VERSION "created by canmatrix"

NS_ :

BS_:

BU_: User ADM_PC_LL25 ADM_PC_BC25 ADM_PC_BP25 ADM_PC_BI25

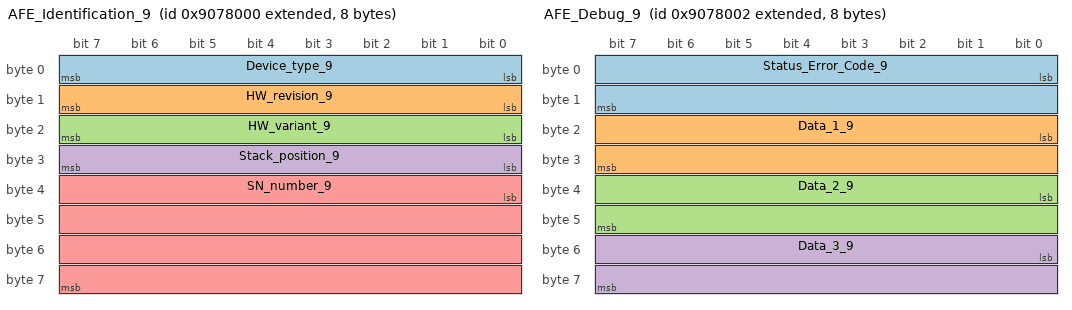
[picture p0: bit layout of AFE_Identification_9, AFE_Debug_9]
BO_ 2298970112 AFE_Identification_9: 8 ADM_PC_BP25
 SG_ Device_type_9 : 0|8@1+ (1,0) [0|255] "" Vector__XXX
 SG_ HW_revision_9 : 8|8@1+ (1,0) [0|255] "" Vector__XXX
 SG_ HW_variant_9 : 16|8@1+ (1,0) [0|255] "" Vector__XXX
 SG_ Stack_position_9 : 24|8@1+ (1,0) [0|255] "" Vector__XXX
 SG_ SN_number_9 : 32|32@1+ (1,0) [0|4294967295] "" Vector__XXX

BO_ 2298970113 AFE_FwInfo_9: 8 ADM_PC_BP25
 SG_ FW_info_mux_9 M : 56|8@1+ (1,0) [0|255] "" Vector__XXX
 SG_ FW_revision_0_9 m0 : 0|8@1+ (1,0) [0|255] "" Vector__XXX
 SG_ FW_revision_1_9 m0 : 8|8@1+ (1,0) [0|255] "" Vector__XXX
 SG_ FW_revision_2_9 m0 : 16|8@1+ (1,0) [0|255] "" Vector__XXX
 SG_ FW_revision_3_9 m0 : 24|8@1+ (1,0) [0|255] "" Vector__XXX
 SG_ FW_revision_4_9 m0 : 32|8@1+ (1,0) [0|255] "" Vector__XXX
 SG_ FW_revision_5_9 m0 : 40|8@1+ (1,0) [0|255] "" Vector__XXX
 SG_ FW_revision_6_9 m0 : 48|8@1+ (1,0) [0|255] "" Vector__XXX
 SG_ FW_revision_7_9 m1 : 0|8@1+ (1,0) [0|255] "" Vector__XXX
 SG_ FW_revision_8_9 m1 : 8|8@1+ (1,0) [0|255] "" Vector__XXX
 SG_ FW_revision_9_9 m1 : 16|8@1+ (1,0) [0|255] "" Vector__XXX
 SG_ FW_revision_10_9 m1 : 24|8@1+ (1,0) [0|255] "" Vector__XXX
 SG_ FW_revision_11_9 m1 : 32|8@1+ (1,0) [0|255] "" Vector__XXX
 SG_ FW_revision_12_9 m1 : 40|8@1+ (1,0) [0|255] "" Vector__XXX
 SG_ FW_revision_13_9 m1 : 48|8@1+ (1,0) [0|255] "" Vector__XXX
 SG_ FW_datecode_0_9 m2 : 0|8@1+ (1,0) [0|255] "" Vector__XXX
 SG_ FW_datecode_1_9 m2 : 8|8@1+ (1,0) [0|255] "" Vector__XXX
 SG_ FW_datecode_2_9 m2 : 16|8@1+ (1,0) [0|255] "" Vector__XXX
 SG_ FW_datecode_3_9 m2 : 24|8@1+ (1,0) [0|255] "" Vector__XXX
 SG_ FW_datecode_4_9 m2 : 32|8@1+ (1,0) [0|255] "" Vector__XXX
 SG_ FW_datecode_5_9 m2 : 40|8@1+ (1,0) [0|255] "" Vector__XXX
 SG_ FW_datecode_6_9 m2 : 48|8@1+ (1,0) [0|255] "" Vector__XXX
 SG_ FW_datecode_7_9 m3 : 0|8@1+ (1,0) [0|255] "" Vector__XXX
 SG_ FW_datecode_8_9 m3 : 8|8@1+ (1,0) [0|255] "" Vector__XXX
 SG_ FW_datecode_9_9 m3 : 16|8@1+ (1,0) [0|255] "" Vector__XXX
 SG_ FW_datecode_10_9 m3 : 24|8@1+ (1,0) [0|255] "" Vector__XXX
 SG_ FW_datecode_11_9 m3 : 32|8@1+ (1,0) [0|255] "" Vector__XXX
 SG_ FW_datecode_12_9 m3 : 40|8@1+ (1,0) [0|255] "" Vector__XXX
 SG_ FW_datecode_13_9 m3 : 48|8@1+ (1,0) [0|255] "" Vector__XXX

BO_ 2298970125 _AFE_Boot_FwInfo_9: 8 ADM_PC_BP25
 SG_ Boot_FW_info_mux_9 M : 56|8@1+ (1,0) [0|255] "" Vector__XXX
 SG_ FW_revision_0_9 m0 : 0|8@1+ (1,0) [0|255] "" Vector__XXX
 SG_ FW_revision_1_9 m0 : 8|8@1+ (1,0) [0|255] "" Vector__XXX
 SG_ FW_revision_2_9 m0 : 16|8@1+ (1,0) [0|255] "" Vector__XXX
 SG_ FW_revision_3_9 m0 : 24|8@1+ (1,0) [0|255] "" Vector__XXX
 SG_ FW_revision_4_9 m0 : 32|8@1+ (1,0) [0|255] "" Vector__XXX
 SG_ FW_revision_5_9 m0 : 40|8@1+ (1,0) [0|255] "" Vector__XXX
 SG_ FW_revision_6_9 m0 : 48|8@1+ (1,0) [0|255] "" Vector__XXX
 SG_ FW_revision_7_9 m1 : 0|8@1+ (1,0) [0|255] "" Vector__XXX
 SG_ FW_revision_8_9 m1 : 8|8@1+ (1,0) [0|255] "" Vector__XXX
 SG_ FW_revision_9_9 m1 : 16|8@1+ (1,0) [0|255] "" Vector__XXX
 SG_ FW_revision_10_9 m1 : 24|8@1+ (1,0) [0|255] "" Vector__XXX
 SG_ FW_revision_11_9 m1 : 32|8@1+ (1,0) [0|255] "" Vector__XXX
 SG_ FW_revision_12_9 m1 : 40|8@1+ (1,0) [0|255] "" Vector__XXX
 SG_ FW_revision_13_9 m1 : 48|8@1+ (1,0) [0|255] "" Vector__XXX
 SG_ FW_datecode_0_9 m2 : 0|8@1+ (1,0) [0|255] "" Vector__XXX
 SG_ FW_datecode_1_9 m2 : 8|8@1+ (1,0) [0|255] "" Vector__XXX
 SG_ FW_datecode_2_9 m2 : 16|8@1+ (1,0) [0|255] "" Vector__XXX
 SG_ FW_datecode_3_9 m2 : 24|8@1+ (1,0) [0|255] "" Vector__XXX
 SG_ FW_datecode_4_9 m2 : 32|8@1+ (1,0) [0|255] "" Vector__XXX
 SG_ FW_datecode_5_9 m2 : 40|8@1+ (1,0) [0|255] "" Vector__XXX
 SG_ FW_datecode_6_9 m2 : 48|8@1+ (1,0) [0|255] "" Vector__XXX
 SG_ FW_datecode_7_9 m3 : 0|8@1+ (1,0) [0|255] "" Vector__XXX
 SG_ FW_datecode_8_9 m3 : 8|8@1+ (1,0) [0|255] "" Vector__XXX
 SG_ FW_datecode_9_9 m3 : 16|8@1+ (1,0) [0|255] "" Vector__XXX
 SG_ FW_datecode_10_9 m3 : 24|8@1+ (1,0) [0|255] "" Vector__XXX
 SG_ FW_datecode_11_9 m3 : 32|8@1+ (1,0) [0|255] "" Vector__XXX
 SG_ FW_datecode_12_9 m3 : 40|8@1+ (1,0) [0|255] "" Vector__XXX
 SG_ FW_datecode_13_9 m3 : 48|8@1+ (1,0) [0|255] "" Vector__XXX

BO_ 2298970114 AFE_Debug_9: 8 ADM_PC_BP25
 SG_ Status_Error_Code_9 : 0|16@1+ (1,0) [0|65535] "" Vector__XXX
 SG_ Data_1_9 : 16|16@1+ (1,0) [0|65535] "" Vector__XXX
 SG_ Data_2_9 : 32|16@1+ (1,0) [0|65535] "" Vector__XXX
 SG_ Data_3_9 : 48|16@1+ (1,0) [0|65535] "" Vector__XXX

BO_ 2298970119 AFE_Status_9: 8 ADM_PC_BP25
 SG_ Running_9 : 0|1@1+ (1,0) [0|1] "" Vector__XXX
 SG_ PWM_9 : 1|1@1+ (1,0) [0|1] "" Vector__XXX
 SG_ Current_dc_loop_mode_9 : 2|1@1+ (1,0) [0|1] "" Vector__XXX
 SG_ Current_ac_loop_mode_9 : 3|1@1+ (1,0) [0|1] "" Vector__XXX
 SG_ Buck_9 : 5|1@1+ (1,0) [0|1] "" Vector__XXX
 SG_ Boost_9 : 6|1@1+ (1,0) [0|1] "" Vector__XXX
 SG_ Precharge_dc_buck_mode_9 : 7|1@1+ (1,0) [0|1] "" Vector__XXX
 SG_ Precharge_dc_boost_mode_9 : 8|1@1+ (1,0) [0|1] "" Vector__XXX
 SG_ Rectifier_3ph_9 : 9|1@1+ (1,0) [0|1] "" Vector__XXX
 SG_ Stack_mode_9 : 10|1@1+ (1,0) [0|1] "" Vector__XXX
 SG_ Master_9 : 11|1@1+ (1,0) [0|1] "" Vector__XXX
 SG_ Slave_9 : 12|1@1+ (1,0) [0|1] "" Vector__XXX
 SG_ Inverter_1ph_9 : 13|1@1+ (1,0) [0|1] "" Vector__XXX
 SG_ Boost_Neutral_9 : 14|1@1+ (1,0) [0|1] "" Vector__XXX
 SG_ Rectifier_1ph_9 : 15|1@1+ (1,0) [0|1] "" Vector__XXX
 SG_ Inverter_3ph_9 : 16|1@1+ (1,0) [0|1] "" Vector__XXX
 SG_ Ready_9 : 17|1@1+ (1,0) [0|1] "" Vector__XXX
 SG_ Inverter_1ph_Sync_9 : 18|1@1+ (1,0) [0|1] "" Vector__XXX
 SG_ Neutral_9 : 19|1@1+ (1,0) [0|1] "" Vector__XXX
 SG_ Rectifier_1ph_Buck_9 : 20|1@1+ (1,0) [0|1] "" Vector__XXX
 SG_ Inverter_1ph_Boost_9 : 21|1@1+ (1,0) [0|1] "" Vector__XXX
 SG_ Rectifier_distributed_9 : 22|1@1+ (1,0) [0|1] "" Vector__XXX
 SG_ MPPT_buck_9 : 23|1@1+ (1,0) [0|1] "" Vector__XXX
 SG_ MPPT_boost_9 : 24|1@1+ (1,0) [0|1] "" Vector__XXX
 SG_ Buck_2p_float_9 : 25|1@1+ (1,0) [0|1] "" Vector__XXX
 SG_ Inverter_1ph_Distributed_9 : 26|1@1+ (1,0) [0|1] "" Vector__XXX

BO_ 2298970118 AFE_Faults_9: 3 ADM_PC_BP25
 SG_ Protection_trip_internal_9 : 0|1@1+ (1,0) [0|1] "" Vector__XXX
 SG_ Protection_trip_external_9 : 1|1@1+ (1,0) [0|1] "" Vector__XXX
 SG_ Phase_U_overcurrent_9 : 2|1@1+ (1,0) [0|1] "" Vector__XXX
 SG_ Phase_U_overvoltage_9 : 3|1@1+ (1,0) [0|1] "" Vector__XXX
 SG_ Phase_U_undervoltage_9 : 4|1@1+ (1,0) [0|1] "" Vector__XXX
 SG_ Phase_V_overvoltage_9 : 5|1@1+ (1,0) [0|1] "" Vector__XXX
 SG_ Phase_V_undervoltage_9 : 6|1@1+ (1,0) [0|1] "" Vector__XXX
 SG_ Phase_V_overcurrent_9 : 7|1@1+ (1,0) [0|1] "" Vector__XXX
 SG_ Phase_W_overvoltage_9 : 8|1@1+ (1,0) [0|1] "" Vector__XXX
 SG_ Phase_W_undervoltage_9 : 9|1@1+ (1,0) [0|1] "" Vector__XXX
 SG_ Phase_W_overcurrent_9 : 10|1@1+ (1,0) [0|1] "" Vector__XXX
 SG_ DC_undervoltage_9 : 11|1@1+ (1,0) [0|1] "" Vector__XXX
 SG_ DC_overvoltage_9 : 12|1@1+ (1,0) [0|1] "" Vector__XXX
 SG_ MOSFET_overtemperature_9 : 13|1@1+ (1,0) [0|1] "" Vector__XXX
 SG_ Inductor_overtemperature_9 : 14|1@1+ (1,0) [0|1] "" Vector__XXX
 SG_ Keep_Alive_not_served_9 : 15|1@1+ (1,0) [0|1] "" Vector__XXX
 SG_ PLL_not_locked_9 : 16|1@1+ (1,0) [0|1] "" Vector__XXX
 SG_ NFO_9 : 20|1@1+ (1,0) [0|1] "" Vector__XXX
 SG_ Measurement_system_failure_9 : 21|1@1+ (1,0) [0|1] "" Vector__XXX
 SG_ EEPROM_failure_9 : 22|1@1+ (1,0) [0|1] "" Vector__XXX
 SG_ System_9 : 23|1@1+ (1,0) [0|1] "" Vector__XXX

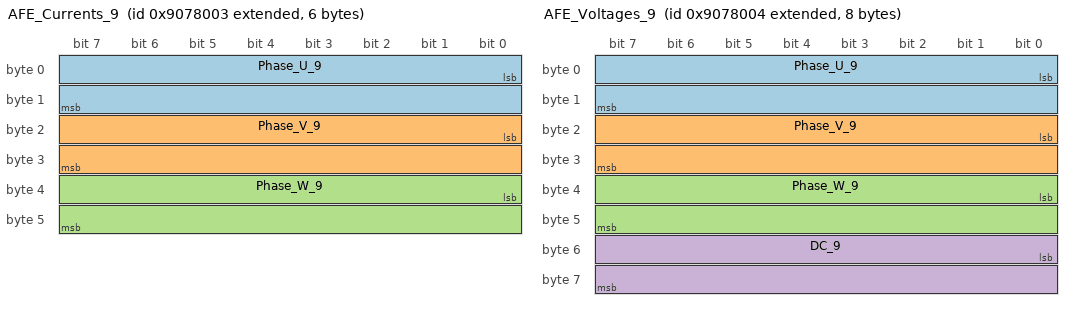
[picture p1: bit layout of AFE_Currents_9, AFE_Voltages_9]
BO_ 2298970115 AFE_Currents_9: 6 ADM_PC_BP25
 SG_ Phase_U_9 : 0|16@1- (0.01,0) [-327.68|327.67] "A" Vector__XXX
 SG_ Phase_V_9 : 16|16@1- (0.01,0) [-327.68|327.67] "A" Vector__XXX
 SG_ Phase_W_9 : 32|16@1- (0.01,0) [-327.68|327.67] "A" Vector__XXX

BO_ 2298970128 AFE_DC_Bus_current_9: 2 ADM_PC_BP25
 SG_ Bus_current_9 : 0|16@1- (0.01,0) [-327.68|327.67] "A" Vector__XXX

BO_ 2298970126 _AFE_Broadcast_9: 8 ADM_PC_BP25
 SG_ Diagnostics_Index_9 M : 56|8@1+ (1,0) [0|255] "" Vector__XXX
 SG_ Phase_U_9 m1 : 8|16@1- (0.01,0) [-327.68|327.67] "A" ADM_PC_BP25
 SG_ Phase_V_9 m1 : 24|16@1- (0.01,0) [-327.68|327.67] "A" ADM_PC_BP25
 SG_ Phase_W_9 m1 : 40|16@1- (0.01,0) [-327.68|327.67] "A" ADM_PC_BP25
 SG_ Stack_position_9 : 0|5@1+ (1,0) [0|31] "" ADM_PC_BP25
 SG_ Group_ID_9 : 5|3@1+ (1,0) [0|7] "" ADM_PC_BP25

BO_ 2298970116 AFE_Voltages_9: 8 ADM_PC_BP25
 SG_ Phase_U_9 : 0|16@1- (0.1,0) [-3276.8|3276.7] "V" Vector__XXX
 SG_ Phase_V_9 : 16|16@1- (0.1,0) [-3276.8|3276.7] "V" Vector__XXX
 SG_ Phase_W_9 : 32|16@1- (0.1,0) [-3276.8|3276.7] "V" Vector__XXX
 SG_ DC_9 : 48|16@1- (0.1,0) [-3276.8|3276.7] "V" Vector__XXX

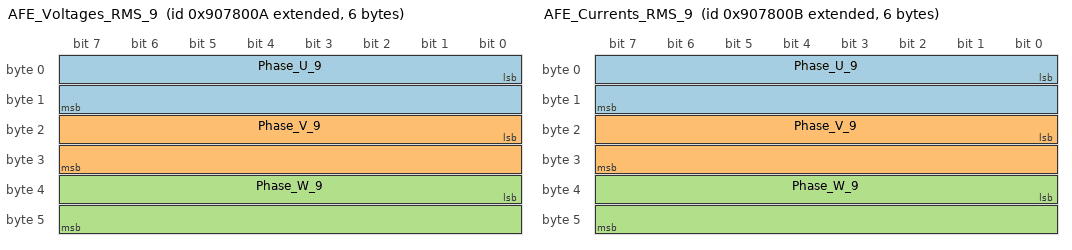
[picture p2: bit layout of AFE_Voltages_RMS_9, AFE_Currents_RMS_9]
BO_ 2298970122 AFE_Voltages_RMS_9: 6 ADM_PC_BP25
 SG_ Phase_U_9 : 0|16@1+ (0.1,0) [0|6553.5] "V" Vector__XXX
 SG_ Phase_V_9 : 16|16@1+ (0.1,0) [0|6553.5] "V" Vector__XXX
 SG_ Phase_W_9 : 32|16@1+ (0.1,0) [0|6553.5] "V" Vector__XXX

BO_ 2298970123 AFE_Currents_RMS_9: 6 ADM_PC_BP25
 SG_ Phase_U_9 : 0|16@1+ (0.01,0) [0.00|655.35] "A" Vector__XXX
 SG_ Phase_V_9 : 16|16@1+ (0.01,0) [0.00|655.35] "A" Vector__XXX
 SG_ Phase_W_9 : 32|16@1+ (0.01,0) [0.00|655.35] "A" Vector__XXX

BO_ 2298970124 AFE_Mains_9: 4 ADM_PC_BP25
 SG_ Frequency_9 : 0|16@1+ (0.01,0) [0.00|655.35] "Hz" Vector__XXX
 SG_ Phase_9 : 16|16@1- (0.1,0) [-3276.8|3276.7] "Deg." Vector__XXX

BO_ 2298970117 AFE_Temperatures_9: 4 ADM_PC_BP25
 SG_ Temp_Bridge_9 : 0|16@1- (0.01,0) [-327.68|327.67] "°C" Vector__XXX
 SG_ Temp_Inductors_9 : 16|16@1- (0.01,0) [-327.68|327.67] "°C" Vector__XXX

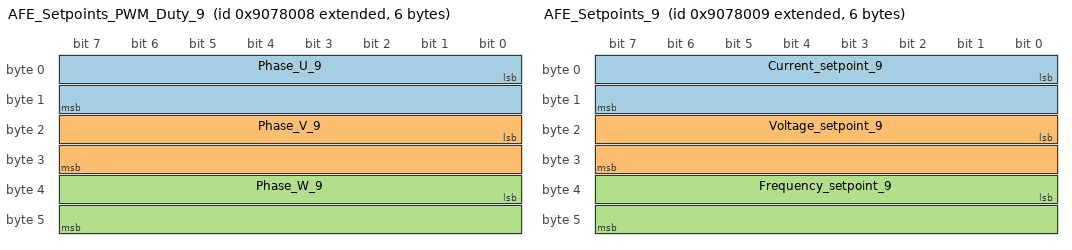
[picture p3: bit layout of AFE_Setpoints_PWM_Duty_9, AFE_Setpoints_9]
BO_ 2298970120 AFE_Setpoints_PWM_Duty_9: 6 ADM_PC_BP25
 SG_ Phase_U_9 : 0|16@1+ (0.001525902,0) [0E-009|99.999987570] "%" Vector__XXX
 SG_ Phase_V_9 : 16|16@1+ (0.001525902,0) [0E-009|99.999987570] "%" Vector__XXX
 SG_ Phase_W_9 : 32|16@1+ (0.001525902,0) [0E-009|99.999987570] "%" Vector__XXX

BO_ 2298970121 AFE_Setpoints_9: 6 ADM_PC_BP25
 SG_ Current_setpoint_9 : 0|16@1- (0.01,0) [-327.68|327.67] "A" Vector__XXX
 SG_ Voltage_setpoint_9 : 16|16@1+ (0.1,0) [0|6553.5] "V" Vector__XXX
 SG_ Frequency_setpoint_9 : 32|16@1+ (0.01,0) [0.00|655.35] "Hz" Vector__XXX

BO_ 2298937440 AFE_Keep_Alive_9: 1 User
 SG_ Keep_Alive_Enable_9 : 0|1@1+ (1,0) [0|1] "" ADM_PC_BP25

BO_ 2298937408 AFE_Mode_Control_9: 8 User
 SG_ Converter_ON_9 : 0|1@1+ (1,0) [0|1] "" ADM_PC_BP25
 SG_ PWM_ON_9 : 1|1@1+ (1,0) [0|1] "" ADM_PC_BP25
 SG_ DC_Current_feedback_ON_9 : 2|1@1+ (1,0) [0|1] "" ADM_PC_BP25
 SG_ AC_Current_feedback_ON_9 : 3|1@1+ (1,0) [0|1] "" ADM_PC_BP25
 SG_ Buck_ON_9 : 5|1@1+ (1,0) [0|1] "" ADM_PC_BP25
 SG_ Boost_ON_9 : 6|1@1+ (1,0) [0|1] "" ADM_PC_BP25
 SG_ Rectifier_3ph_ON_9 : 9|1@1+ (1,0) [0|1] "" ADM_PC_BP25
 SG_ Inverter_1ph_ON_9 : 10|1@1+ (1,0) [0|1] "" ADM_PC_BP25
 SG_ Rectifier_1ph_ON_9 : 11|1@1+ (1,0) [0|1] "" ADM_PC_BP25
 SG_ Boost_Neutral_ON_9 : 12|1@1+ (1,0) [0|1] "" ADM_PC_BP25
 SG_ Inverter_3ph_ON_9 : 13|1@1+ (1,0) [0|1] "" ADM_PC_BP25
 SG_ Inverter_1ph_Sync_ON_9 : 14|1@1+ (1,0) [0|1] "" ADM_PC_BP25
 SG_ Neutral_ON_9 : 15|1@1+ (1,0) [0|1] "" ADM_PC_BP25
 SG_ Rectifier_1ph_Buck_ON_9 : 16|1@1+ (1,0) [0|1] "" ADM_PC_BP25
 SG_ Inverter_1ph_Boost_ON_9 : 17|1@1+ (1,0) [0|1] "" ADM_PC_BP25
 SG_ Rectifier_Distributed_ON_9 : 18|1@1+ (1,0) [0|1] "" ADM_PC_BP25
 SG_ MPPT_buck_ON_9 : 19|1@1+ (1,0) [0|1] "" ADM_PC_BP25
 SG_ MPPT_boost_ON_9 : 20|1@1+ (1,0) [0|1] "" ADM_PC_BP25
 SG_ Buck_2p_float_ON_9 : 21|1@1+ (1,0) [0|1] "" ADM_PC_BP25
 SG_ Inverter_1ph_Distributed_ON_9 : 22|1@1+ (1,0) [0|1] "" ADM_PC_BP25

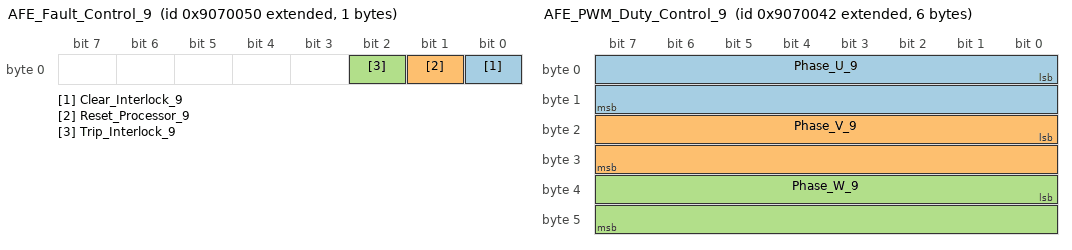
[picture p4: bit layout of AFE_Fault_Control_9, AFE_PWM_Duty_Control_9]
BO_ 2298937424 AFE_Fault_Control_9: 1 User
 SG_ Clear_Interlock_9 : 0|1@1+ (1,0) [0|1] "" ADM_PC_BP25
 SG_ Reset_Processor_9 : 1|1@1+ (1,0) [0|1] "" ADM_PC_BP25
 SG_ Trip_Interlock_9 : 2|1@1+ (1,0) [0|1] "" ADM_PC_BP25

BO_ 2298937409 AFE_Reactive_Current_Setpoint_Co: 2 User
 SG_ Reactive_current_setpoint_9 : 0|16@1- (0.01,0) [-150|150] "A" ADM_PC_BP25

BO_ 2298937410 AFE_PWM_Duty_Control_9: 6 User
 SG_ Phase_U_9 : 0|16@1+ (0.001525902,0) [0E-009|99.999987570] "%" ADM_PC_BP25
 SG_ Phase_V_9 : 16|16@1+ (0.001525902,0) [0E-009|99.999987570] "%" ADM_PC_BP25
 SG_ Phase_W_9 : 32|16@1+ (0.001525902,0) [0E-009|99.999987570] "%" ADM_PC_BP25

BO_ 2298937411 AFE_Current_Setpoint_Control_9: 2 User
 SG_ Current_setpoint_9 : 0|16@1- (0.01,0) [-150|150] "A" ADM_PC_BP25

BO_ 2298937412 AFE_Voltage_Setpoint_Control_9: 2 User
 SG_ Voltage_setpoint_9 : 0|16@1+ (0.1,0) [0|1500] "V" ADM_PC_BP25

BO_ 2298937416 AFE_Frequency_Setpoint_Control_9: 2 User
 SG_ Frequency_setpoint_9 : 0|16@1+ (0.01,0) [40|70] "Hz" ADM_PC_BP25

BO_ 2298937417 AFE_Phase_Setpoint_Control_9: 2 User
 SG_ Phase_setpoint_9 : 0|16@1+ (1,0) [0|360] "deg" ADM_PC_BP25

BO_ 2298937456 AFE_Rectifier_Setpoint_Control_9: 8 User
 SG_ Voltage_setpoint_2_9 : 0|16@1+ (0.1,0) [0|1500] "V" ADM_PC_BP25
 SG_ Current_setpoint_2_9 : 16|16@1- (0.01,0) [-150|150] "A" ADM_PC_BP25

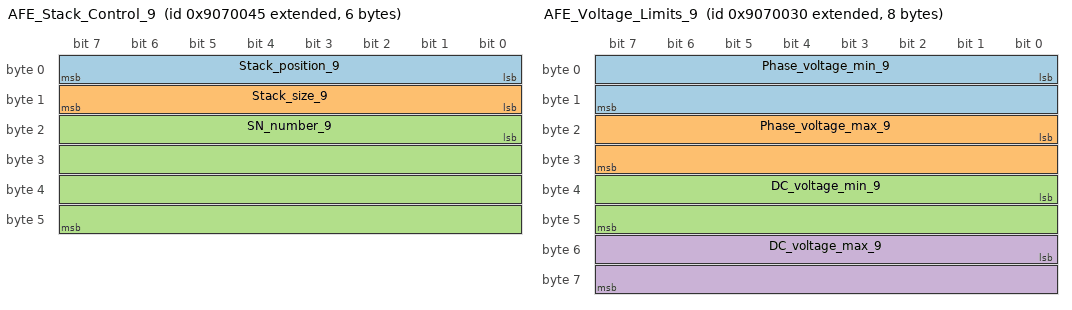
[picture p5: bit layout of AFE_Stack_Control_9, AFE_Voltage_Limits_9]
BO_ 2298937413 AFE_Stack_Control_9: 6 User
 SG_ Stack_position_9 : 0|8@1+ (1,0) [0|255] "" ADM_PC_BP25
 SG_ Stack_size_9 : 8|8@1+ (1,0) [0|255] "" ADM_PC_BP25
 SG_ SN_number_9 : 16|32@1+ (1,0) [0|4294967295] "" ADM_PC_BP25

BO_ 2298937392 AFE_Voltage_Limits_9: 8 User
 SG_ Phase_voltage_min_9 : 0|16@1- (0.1,0) [0|3276.7] "V" ADM_PC_BP25
 SG_ Phase_voltage_max_9 : 16|16@1- (0.1,0) [-3276.8|850] "V" ADM_PC_BP25
 SG_ DC_voltage_min_9 : 32|16@1- (0.1,0) [0|3276.7] "V" ADM_PC_BP25
 SG_ DC_voltage_max_9 : 48|16@1- (0.1,0) [-3276.8|850] "V" ADM_PC_BP25

BO_ 2298937393 AFE_Current_Limits_9: 4 User
 SG_ Phase_current_min_9 : 0|16@1- (0.01,0) [-60|60] "A" ADM_PC_BP25
 SG_ Phase_current_max_9 : 16|16@1- (0.01,0) [-60|60] "A" ADM_PC_BP25

BO_ 2298937420 AFE_Group_Control_9: 1 User
 SG_ Group_ID_9 : 0|8@1+ (1,0) [0|255] "" ADM_PC_BP25

BO_ 2298970127 AFE_Group_Info_9: 1 ADM_PC_BP25
 SG_ Group_ID_9 : 0|8@1+ (1,0) [0|255] "" Vector__XXX

BO_ 2298937441 AFE_System_Flags_Control_9: 8 User
 SG_ Factory_mode_9 : 0|1@1+ (1,0) [0|1] "" ADM_PC_BP25
 SG_ Silent_CAN_mode_9 : 1|1@1+ (1,0) [0|1] "" ADM_PC_BP25

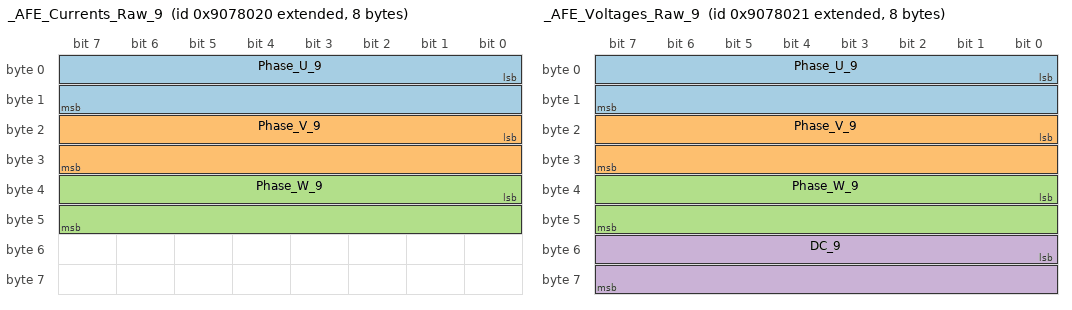
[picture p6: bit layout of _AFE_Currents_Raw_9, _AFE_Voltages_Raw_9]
BO_ 2298970144 _AFE_Currents_Raw_9: 8 ADM_PC_BP25
 SG_ Phase_U_9 : 0|16@1- (1,0) [-32768|32767] "" Vector__XXX
 SG_ Phase_V_9 : 16|16@1- (1,0) [-32768|32767] "" Vector__XXX
 SG_ Phase_W_9 : 32|16@1- (1,0) [-32768|32767] "" Vector__XXX

BO_ 2298970145 _AFE_Voltages_Raw_9: 8 ADM_PC_BP25
 SG_ Phase_U_9 : 0|16@1- (1,0) [-32768|32767] "" Vector__XXX
 SG_ Phase_V_9 : 16|16@1- (1,0) [-32768|32767] "" Vector__XXX
 SG_ Phase_W_9 : 32|16@1- (1,0) [-32768|32767] "" Vector__XXX
 SG_ DC_9 : 48|16@1- (1,0) [-32768|32767] "" Vector__XXX

BO_ 2298937418 _AFE_ADC_Calibration_Mode_9: 1 User
 SG_ Calibration_Index_9 M : 2|5@1+ (1,0) [0|31] "" Vector__XXX
 SG_ Current_U_9 m1 : 0|2@1+ (1,0) [0|3] "" ADM_PC_BP25
 SG_ Current_V_9 m2 : 0|2@1+ (1,0) [0|3] "" ADM_PC_BP25
 SG_ Current_W_9 m3 : 0|2@1+ (1,0) [0|3] "" ADM_PC_BP25
 SG_ Voltage_U_9 m4 : 0|2@1+ (1,0) [0|3] "" ADM_PC_BP25
 SG_ Voltage_V_9 m5 : 0|2@1+ (1,0) [0|3] "" ADM_PC_BP25
 SG_ Voltage_W_9 m6 : 0|2@1+ (1,0) [0|3] "" ADM_PC_BP25
 SG_ Voltage_DC_9 m7 : 0|2@1+ (1,0) [0|3] "" ADM_PC_BP25
 SG_ start_9 : 7|1@1+ (1,0) [0|1] "" ADM_PC_BP25

BO_ 2298937419 _AFE_ADC_Calibration_Setpoint_9: 3 User
 SG_ Calibration_Index_9 M : 16|5@1+ (1,0) [0|31] "" Vector__XXX
 SG_ Current_U_9 m1 : 0|16@1- (0.01,0) [-100|100] "A" ADM_PC_BP25
 SG_ Current_V_9 m2 : 0|16@1- (0.01,0) [-100|100] "A" ADM_PC_BP25
 SG_ Current_W_9 m3 : 0|16@1- (0.01,0) [-100|100] "A" ADM_PC_BP25
 SG_ Voltage_U_9 m4 : 0|16@1+ (0.1,0) [0|1500] "V" ADM_PC_BP25
 SG_ Voltage_V_9 m5 : 0|16@1+ (0.1,0) [0|1500] "V" ADM_PC_BP25
 SG_ Voltage_W_9 m6 : 0|16@1+ (0.1,0) [0|1500] "V" ADM_PC_BP25
 SG_ Voltage_DC_9 m7 : 0|16@1+ (0.1,0) [0|1500] "V" ADM_PC_BP25
 SG_ point_9 : 21|3@1+ (1,0) [0|7] "" ADM_PC_BP25

BO_ 2298937414 _AFE_Calibration_Offset_Update_9: 6 User
 SG_ Calibration_Index_9 M : 16|16@1+ (1,0) [0|65535] "" Vector__XXX
 SG_ Current_U_9 m0 : 0|16@1- (1,0) [-32768|32767] "ADC Counts" ADM_PC_BP25
 SG_ Current_V_9 m1 : 0|16@1- (1,0) [-32768|32767] "ADC Counts" ADM_PC_BP25
 SG_ Current_W_9 m2 : 0|16@1- (1,0) [-32768|32767] "ADC Counts" ADM_PC_BP25
 SG_ Voltage_U_9 m3 : 0|16@1- (1,0) [-32768|32767] "ADC Counts" ADM_PC_BP25
 SG_ Voltage_V_9 m4 : 0|16@1- (1,0) [-32768|32767] "ADC Counts" ADM_PC_BP25
 SG_ Voltage_W_9 m5 : 0|16@1- (1,0) [-32768|32767] "ADC Counts" ADM_PC_BP25
 SG_ Voltage_DC_9 m6 : 0|16@1- (1,0) [-32768|32767] "ADC Counts" ADM_PC_BP25
 SG_ CRC_9 : 32|16@1+ (1,0) [0|65535] "-" ADM_PC_BP25

BO_ 2298937415 _AFE_Calibration_Scale_Update_9: 6 User
 SG_ Calibration_Index_9 M : 16|16@1+ (1,0) [0|65535] "" Vector__XXX
 SG_ Current_U_9 m0 : 0|16@1- (0.0000152587890625,0) [-0.5000000000000000|0.4999847412109375] "scale = 1.0 + value" ADM_PC_BP25
 SG_ Current_V_9 m1 : 0|16@1- (0.0000152587890625,0) [-0.5000000000000000|0.4999847412109375] "scale = 1.0 + value" ADM_PC_BP25
 SG_ Current_W_9 m2 : 0|16@1- (0.0000152587890625,0) [-0.5000000000000000|0.4999847412109375] "scale = 1.0 + value" ADM_PC_BP25
 SG_ Voltage_U_9 m3 : 0|16@1- (0.0000152587890625,0) [-0.5000000000000000|0.4999847412109375] "scale = 1.0 + value" ADM_PC_BP25
 SG_ Voltage_V_9 m4 : 0|16@1- (0.0000152587890625,0) [-0.5000000000000000|0.4999847412109375] "scale = 1.0 + value" ADM_PC_BP25
 SG_ Voltage_W_9 m5 : 0|16@1- (0.0000152587890625,0) [-0.5000000000000000|0.4999847412109375] "scale = 1.0 + value" ADM_PC_BP25
 SG_ Voltage_DC_9 m6 : 0|16@1- (0.0000152587890625,0) [-0.5000000000000000|0.4999847412109375] "scale = 1.0 + value" ADM_PC_BP25
 SG_ CRC_9 : 32|16@1+ (1,0) [0|65535] "-" ADM_PC_BP25

BO_ 2298970193 _AFE_Calibration_Adc_Scale_9: 6 ADM_PC_BP25
 SG_ Adc_Index_9 M : 32|16@1+ (1,0) [0|65535] "" Vector__XXX
 SG_ Current_U_9 m0 : 0|32@1+ (1,0) [0|4294967295] "1 / adc_bins" User
 SG_ Current_V_9 m1 : 0|32@1+ (1,0) [0|4294967295] "1 / adc_bins" User
 SG_ Current_W_9 m2 : 0|32@1+ (1,0) [0|4294967295] "1 / adc_bins" User
 SG_ Voltage_U_9 m3 : 0|32@1+ (1,0) [0|4294967295] "1 / adc_bins" User
 SG_ Voltage_V_9 m4 : 0|32@1+ (1,0) [0|4294967295] "1 / adc_bins" User
 SG_ Voltage_W_9 m5 : 0|32@1+ (1,0) [0|4294967295] "1 / adc_bins" User
 SG_ Voltage_DC_9 m6 : 0|32@1+ (1,0) [0|4294967295] "1 / adc_bins" User

BO_ 2298970194 _AFE_Calibration_Adc_Fs_9: 6 ADM_PC_BP25
 SG_ Adc_Index_9 M : 32|16@1+ (1,0) [0|65535] "" Vector__XXX
 SG_ Current_U_9 m0 : 0|32@1+ (1,0) [0|4294967295] "Fullscale" User
 SG_ Current_V_9 m1 : 0|32@1+ (1,0) [0|4294967295] "Fullscale" User
 SG_ Current_W_9 m2 : 0|32@1+ (1,0) [0|4294967295] "Fullscale" User
 SG_ Voltage_U_9 m3 : 0|32@1+ (1,0) [0|4294967295] "Fullscale" User
 SG_ Voltage_V_9 m4 : 0|32@1+ (1,0) [0|4294967295] "Fullscale" User
 SG_ Voltage_W_9 m5 : 0|32@1+ (1,0) [0|4294967295] "Fullscale" User
 SG_ Voltage_DC_9 m6 : 0|32@1+ (1,0) [0|4294967295] "Fullscale" User

BO_ 2298970195 _AFE_Calibration_Adc_Offset_9: 4 ADM_PC_BP25
 SG_ Adc_Index_9 M : 16|16@1+ (1,0) [0|65535] "" Vector__XXX
 SG_ Current_U_9 m0 : 0|16@1- (1,0) [-32768|32767] "-" User
 SG_ Current_V_9 m1 : 0|16@1- (1,0) [-32768|32767] "-" User
 SG_ Current_W_9 m2 : 0|16@1- (1,0) [-32768|32767] "-" User
 SG_ Voltage_U_9 m3 : 0|16@1- (1,0) [-32768|32767] "-" User
 SG_ Voltage_V_9 m4 : 0|16@1- (1,0) [-32768|32767] "-" User
 SG_ Voltage_W_9 m5 : 0|16@1- (1,0) [-32768|32767] "-" User
 SG_ Voltage_DC_9 m6 : 0|16@1- (1,0) [-32768|32767] "-" User

BO_ 2298970196 _AFE_Calibration_Adc_Gain_9: 4 ADM_PC_BP25
 SG_ Adc_Index_9 M : 16|16@1+ (1,0) [0|65535] "" Vector__XXX
 SG_ Current_U_9 m0 : 0|16@1- (1,0) [-32768|32767] "-" User
 SG_ Current_V_9 m1 : 0|16@1- (1,0) [-32768|32767] "-" User
 SG_ Current_W_9 m2 : 0|16@1- (1,0) [-32768|32767] "-" User
 SG_ Voltage_U_9 m3 : 0|16@1- (1,0) [-32768|32767] "-" User
 SG_ Voltage_V_9 m4 : 0|16@1- (1,0) [-32768|32767] "-" User
 SG_ Voltage_W_9 m5 : 0|16@1- (1,0) [-32768|32767] "-" User
 SG_ Voltage_DC_9 m6 : 0|16@1- (1,0) [-32768|32767] "-" User

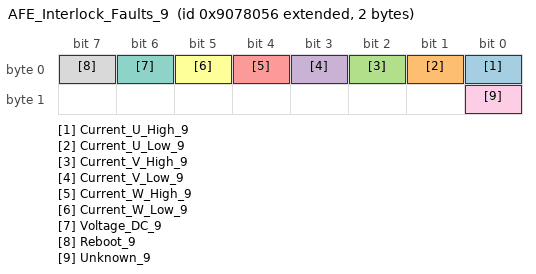
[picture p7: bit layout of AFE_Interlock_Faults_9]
BO_ 2298970198 AFE_Interlock_Faults_9: 2 ADM_PC_BP25
 SG_ Current_U_High_9 : 0|1@1+ (1,0) [0|1] "" Vector__XXX
 SG_ Current_U_Low_9 : 1|1@1+ (1,0) [0|1] "" Vector__XXX
 SG_ Current_V_High_9 : 2|1@1+ (1,0) [0|1] "" Vector__XXX
 SG_ Current_V_Low_9 : 3|1@1+ (1,0) [0|1] "" Vector__XXX
 SG_ Current_W_High_9 : 4|1@1+ (1,0) [0|1] "" Vector__XXX
 SG_ Current_W_Low_9 : 5|1@1+ (1,0) [0|1] "" Vector__XXX
 SG_ Voltage_DC_9 : 6|1@1+ (1,0) [0|1] "" Vector__XXX
 SG_ Reboot_9 : 7|1@1+ (1,0) [0|1] "" Vector__XXX
 SG_ Unknown_9 : 8|1@1+ (1,0) [0|1] "" Vector__XXX

BO_TX_BU_ 2298937408 : User,ADM_PC_LL25,ADM_PC_BC25,ADM_PC_BI25;
BO_TX_BU_ 2298937411 : User,ADM_PC_LL25,ADM_PC_BC25,ADM_PC_BI25;
BO_TX_BU_ 2298937412 : User,ADM_PC_LL25,ADM_PC_BC25,ADM_PC_BI25;
CM_ BO_ 2298970112  "Identification of the device";
CM_ BO_ 2298970113  "Git revision of the DSP firmware";
CM_ BO_ 2298970125  "Git revision of the bootloader firmware.";
CM_ BO_ 2298970114  "Values for debugging of HW/SW problems";
CM_ BO_ 2298970119  "Status bitfield";
CM_ BO_ 2298970118  "Fault bitfield";
CM_ BO_ 2298970115  "Current of phases U, V, W";
CM_ BO_ 2298970128  "Current of of the DC Bus";
CM_ BO_ 2298970126  "All AFEs will listen to this message";
CM_ BO_ 2298970123  "RMS Current of phases U, V, W";
CM_ BO_ 2298970124  "Three-Phase mains health (frequency, phase...)";
CM_ BO_ 2298970117  "Readouts of the module temperature sensors";
CM_ BO_ 2298970120  "Setpoints";
CM_ BO_ 2298970121  "Setpoints";
CM_ BO_ 2298937440  "Keep alive ping message. ";
CM_ BO_ 2298937408  "Operation Mode control: sets the converter operation mode";
CM_ BO_ 2298937424  "Fault Control: actions to clear faults and reset the system";
CM_ BO_ 2298937409  "Reactive power setpoint control.";
CM_ BO_ 2298937410  "PWM duty cycle control";
CM_ BO_ 2298937411  "Current setpoint control";
CM_ BO_ 2298937412  "Voltage setpoint control";
CM_ BO_ 2298937416  "Frequency setpoint control";
CM_ BO_ 2298937417  "Phase setpoint control";
CM_ BO_ 2298937456  "Additional voltage and current setpoints in single-phase rectifier and inverter control modes.";
CM_ BO_ 2298937413  "PFC stack control";
CM_ BO_ 2298937392  "Set the input and output voltage limits (minimum and maximum)";
CM_ BO_ 2298937393  "Set the output current limits (mminimum and maximum)";
CM_ BO_ 2298937420  "Set the Group ID of the device";
CM_ BO_ 2298970127  "Contains the Group ID of the device";
CM_ BO_ 2298937441  "Control the system flags";
CM_ BO_ 2298970144  "Current of phases A and B";
CM_ BO_ 2298970145  "Current of phases A and B";
CM_ BO_ 2298937418  "Automatic ADC calibration.";
CM_ BO_ 2298937419  "Setpoint for automatic ADC calibration.";
CM_ BO_ 2298937414  "Update of the calibration table for offsets.";
CM_ BO_ 2298937415  "Update of the calibration table for scales.";
CM_ BO_ 2298970193  "
                Adc scale (resolution) value of readouts.
            ";
CM_ BO_ 2298970194  "
                Adc fullscale value of readouts.
            ";
CM_ BO_ 2298970195  "
                Readout of ADC calibration data (offset) from EEPROM.
            ";
CM_ BO_ 2298970196  "
                Readout of ADC calibration data (gain) from EEPROM.
            ";
CM_ BO_ 2298970198  "Fault bitfield";

CM_ SG_ 2298970112 Device_type_9 "The device identification field, uniquely identifies the sender in the network";
CM_ SG_ 2298970112 HW_revision_9 "The hardware revision number";
CM_ SG_ 2298970112 HW_variant_9 "The DSP firmware revision number";
CM_ SG_ 2298970112 Stack_position_9 "Position of the module within the stack";
CM_ SG_ 2298970112 SN_number_9 "Unique module serial number";
CM_ SG_ 2298970113 FW_revision_0_9 "Character 0";
CM_ SG_ 2298970113 FW_revision_1_9 "Character 1";
CM_ SG_ 2298970113 FW_revision_2_9 "Character 2";
CM_ SG_ 2298970113 FW_revision_3_9 "Character 3";
CM_ SG_ 2298970113 FW_revision_4_9 "Character 3";
CM_ SG_ 2298970113 FW_revision_5_9 "Character 3";
CM_ SG_ 2298970113 FW_revision_6_9 "Character 3";
CM_ SG_ 2298970113 FW_revision_7_9 "Character 7";
CM_ SG_ 2298970113 FW_revision_8_9 "Character 8";
CM_ SG_ 2298970113 FW_revision_9_9 "Character 9";
CM_ SG_ 2298970113 FW_revision_10_9 "Character 10";
CM_ SG_ 2298970113 FW_revision_11_9 "Character 11";
CM_ SG_ 2298970113 FW_revision_12_9 "Character 12";
CM_ SG_ 2298970113 FW_revision_13_9 "Character 13";
CM_ SG_ 2298970113 FW_datecode_0_9 "Character 0";
CM_ SG_ 2298970113 FW_datecode_1_9 "Character 1";
CM_ SG_ 2298970113 FW_datecode_2_9 "Character 2";
CM_ SG_ 2298970113 FW_datecode_3_9 "Character 3";
CM_ SG_ 2298970113 FW_datecode_4_9 "Character 3";
CM_ SG_ 2298970113 FW_datecode_5_9 "Character 3";
CM_ SG_ 2298970113 FW_datecode_6_9 "Character 3";
CM_ SG_ 2298970113 FW_datecode_7_9 "Character 7";
CM_ SG_ 2298970113 FW_datecode_8_9 "Character 8";
CM_ SG_ 2298970113 FW_datecode_9_9 "Character 9";
CM_ SG_ 2298970113 FW_datecode_10_9 "Character 10";
CM_ SG_ 2298970113 FW_datecode_11_9 "Character 11";
CM_ SG_ 2298970113 FW_datecode_12_9 "Character 12";
CM_ SG_ 2298970113 FW_datecode_13_9 "Character 13";
CM_ SG_ 2298970125 FW_revision_0_9 "Character 0";
CM_ SG_ 2298970125 FW_revision_1_9 "Character 1";
CM_ SG_ 2298970125 FW_revision_2_9 "Character 2";
CM_ SG_ 2298970125 FW_revision_3_9 "Character 3";
CM_ SG_ 2298970125 FW_revision_4_9 "Character 3";
CM_ SG_ 2298970125 FW_revision_5_9 "Character 3";
CM_ SG_ 2298970125 FW_revision_6_9 "Character 3";
CM_ SG_ 2298970125 FW_revision_7_9 "Character 7";
CM_ SG_ 2298970125 FW_revision_8_9 "Character 8";
CM_ SG_ 2298970125 FW_revision_9_9 "Character 9";
CM_ SG_ 2298970125 FW_revision_10_9 "Character 10";
CM_ SG_ 2298970125 FW_revision_11_9 "Character 11";
CM_ SG_ 2298970125 FW_revision_12_9 "Character 12";
CM_ SG_ 2298970125 FW_revision_13_9 "Character 13";
CM_ SG_ 2298970125 FW_datecode_0_9 "Character 0";
CM_ SG_ 2298970125 FW_datecode_1_9 "Character 1";
CM_ SG_ 2298970125 FW_datecode_2_9 "Character 2";
CM_ SG_ 2298970125 FW_datecode_3_9 "Character 3";
CM_ SG_ 2298970125 FW_datecode_4_9 "Character 3";
CM_ SG_ 2298970125 FW_datecode_5_9 "Character 3";
CM_ SG_ 2298970125 FW_datecode_6_9 "Character 3";
CM_ SG_ 2298970125 FW_datecode_7_9 "Character 7";
CM_ SG_ 2298970125 FW_datecode_8_9 "Character 8";
CM_ SG_ 2298970125 FW_datecode_9_9 "Character 9";
CM_ SG_ 2298970125 FW_datecode_10_9 "Character 10";
CM_ SG_ 2298970125 FW_datecode_11_9 "Character 11";
CM_ SG_ 2298970125 FW_datecode_12_9 "Character 12";
CM_ SG_ 2298970125 FW_datecode_13_9 "Character 13";
CM_ SG_ 2298970114 Status_Error_Code_9 "Main status / error code as defined in errno/errno.h";
CM_ SG_ 2298970114 Data_1_9 "Additional information for the error/status";
CM_ SG_ 2298970114 Data_2_9 "Additional information for the error/status";
CM_ SG_ 2298970114 Data_3_9 "Additional information for the error/status";
CM_ SG_ 2298970119 Running_9 "Indicates if converter is running.";
CM_ SG_ 2298970119 PWM_9 "Indicates if converter is in PWM control mode.";
CM_ SG_ 2298970119 Current_dc_loop_mode_9 "Indicates if the current DC loop is enabled.";
CM_ SG_ 2298970119 Current_ac_loop_mode_9 "Indicates if the current AC loop is enabled.";
CM_ SG_ 2298970119 Buck_9 "Indicates if converter is in buck control mode.";
CM_ SG_ 2298970119 Boost_9 "Indicates if converter is in boost control mode.";
CM_ SG_ 2298970119 Precharge_dc_buck_mode_9 "Indicates if the precharge DC mode is enabled - buck direction.";
CM_ SG_ 2298970119 Precharge_dc_boost_mode_9 "Indicates if the precharge DC mode is enabled - boost direction.";
CM_ SG_ 2298970119 Rectifier_3ph_9 "Indicates if converter is in three-phase rectifier control mode.";
CM_ SG_ 2298970119 Stack_mode_9 "Indicates if converter is operating in stack mode.";
CM_ SG_ 2298970119 Master_9 "Indicates if converter is master in the stack.";
CM_ SG_ 2298970119 Slave_9 "Indicates if converter is slave in the stack.";
CM_ SG_ 2298970119 Inverter_1ph_9 "Indicates if converter is in single-phase inverter control mode.";
CM_ SG_ 2298970119 Boost_Neutral_9 "Indicates if converter is in boost control mode with neutral generation.";
CM_ SG_ 2298970119 Rectifier_1ph_9 "Indicates if converter is in single-phase rectifier control mode.";
CM_ SG_ 2298970119 Inverter_3ph_9 "Indicates if converter is in three-phase inverter control mode.";
CM_ SG_ 2298970119 Ready_9 "Indicates if converter is ready for operation.";
CM_ SG_ 2298970119 Inverter_1ph_Sync_9 "Single-phase inverter control mode with phase synchronization.";
CM_ SG_ 2298970119 Neutral_9 "Open-loop neutral generation.";
CM_ SG_ 2298970119 Rectifier_1ph_Buck_9 "Single-phase rectifier with buck on one leg.";
CM_ SG_ 2298970119 Inverter_1ph_Boost_9 "Single-phase inverter with boost on one leg.";
CM_ SG_ 2298970119 Rectifier_distributed_9 "Not available at the moment";
CM_ SG_ 2298970119 MPPT_buck_9 "Not available at the moment";
CM_ SG_ 2298970119 MPPT_boost_9 "Not available at the moment";
CM_ SG_ 2298970119 Buck_2p_float_9 "Buck in phases L1 and L2. Phase L3 is left floating (high impedance)";
CM_ SG_ 2298970119 Inverter_1ph_Distributed_9 "Single-phase inverter mode  distributed";
CM_ SG_ 2298970118 Protection_trip_internal_9 "This flagg is asserted if the interlock is open due to an internal fault condition (self-protection)";
CM_ SG_ 2298970118 Protection_trip_external_9 "This flag is asserted if the interlock is open due to an external condition received in the module.";
CM_ SG_ 2298970118 Phase_U_overcurrent_9 "Indicates an overcurrent event on Phase U. The overcurrent event is triggered when the measured phase current is over the programmed current limit.";
CM_ SG_ 2298970118 Phase_U_overvoltage_9 "Indicates an overvoltage event on Phase U. The overvoltage event is triggered when the measured phase voltage is over the programmed voltage limit.";
CM_ SG_ 2298970118 Phase_U_undervoltage_9 "Indicates an undervoltage event on Phase U. The overvoltage event is triggered when the measured phase voltage is over the programmed voltage limit.";
CM_ SG_ 2298970118 Phase_V_overvoltage_9 "Indicates an overvoltage event on Phase V. The overvoltage event is triggered when the measured phase voltage is over the programmed voltage limit.";
CM_ SG_ 2298970118 Phase_V_undervoltage_9 "Indicates an undervoltage event on Phase U. The overvoltage event is triggered when the measured phase voltage is over the programmed voltage limit.";
CM_ SG_ 2298970118 Phase_V_overcurrent_9 "Indicates an overcurrent event on Phase U. The overcurrent event is triggered when the measured phase current is over the programmed current limit.";
CM_ SG_ 2298970118 Phase_W_overvoltage_9 "Indicates an overvoltage event on Phase U. The overvoltage event is triggered when the measured phase voltage is over the programmed voltage limit.";
CM_ SG_ 2298970118 Phase_W_undervoltage_9 "Indicates an undervoltage event on Phase U. The overvoltage event is triggered when the measured phase voltage is over the programmed voltage limit.";
CM_ SG_ 2298970118 Phase_W_overcurrent_9 "Indicates an overcurrent event on Phase U. The overcurrent event is triggered when the measured phase current is over the programmed current limit.";
CM_ SG_ 2298970118 DC_undervoltage_9 "DC bus undervoltage condition. The undervoltage condition is asserted when the measured dc bus voltage is under the programmed voltage limit.";
CM_ SG_ 2298970118 DC_overvoltage_9 "DC bus overvoltage condition. The overvoltage condition is asserted when the measured dc bus voltage is over the programmed voltage limit.";
CM_ SG_ 2298970118 MOSFET_overtemperature_9 "This flag is asserted when the temperature of the MOSFET block is too high.";
CM_ SG_ 2298970118 Inductor_overtemperature_9 "This flag is asserted when the temperature of the inductor block is too high.";
CM_ SG_ 2298970118 Keep_Alive_not_served_9 "The Keep Alive feature is enabled but it was not served with the periodic message.";
CM_ SG_ 2298970118 PLL_not_locked_9 "Flag asserted when in rectifier modes, the PLL went out of lock condition";
CM_ SG_ 2298970118 Measurement_system_failure_9 "The voltages/currents measurement system is malfunctionning, and readouts are not guaranteed to be accurate.";
CM_ SG_ 2298970118 EEPROM_failure_9 "The configuration EEPROM failed to load or save the module configuration.";
CM_ SG_ 2298970115 Phase_U_9 "Phase current is the MOSFET loop current, in the branch U of the converter.";
CM_ SG_ 2298970115 Phase_V_9 "Phase current is the MOSFET loop current, in the branch V of the converter.";
CM_ SG_ 2298970115 Phase_W_9 "Phase current is the MOSFET loop current, in the branch W of the converter.";
CM_ SG_ 2298970128 Bus_current_9 "DC Bus current is possitive when current goes from input to output";
CM_ SG_ 2298970126 Phase_U_9 "Phase current is the MOSFET loop current, in the branch U of the converter.";
CM_ SG_ 2298970126 Phase_V_9 "Phase current is the MOSFET loop current, in the branch V of the converter.";
CM_ SG_ 2298970126 Phase_W_9 "Phase current is the MOSFET loop current, in the branch W of the converter.";
CM_ SG_ 2298970126 Stack_position_9 "Sender Stack position";
CM_ SG_ 2298970126 Group_ID_9 "Sender Group ID";
CM_ SG_ 2298970123 Phase_U_9 "RMS Phase current is the MOSFET loop current, in the branch U of the converter.";
CM_ SG_ 2298970123 Phase_V_9 "RMS Phase current is the MOSFET loop current, in the branch V of the converter.";
CM_ SG_ 2298970123 Phase_W_9 "RMS Phase current is the MOSFET loop current, in the branch W of the converter.";
CM_ SG_ 2298970124 Frequency_9 "Frequency of Three-Phase system";
CM_ SG_ 2298970124 Phase_9 "Phase of Three-Phase system";
CM_ SG_ 2298970117 Temp_Bridge_9 "Temperature of the MOSFET block";
CM_ SG_ 2298970117 Temp_Inductors_9 "Temperature of the inductors";
CM_ SG_ 2298970120 Phase_U_9 "The actual PWM duty cycle setpoint";
CM_ SG_ 2298970120 Phase_V_9 "The actual PWM duty cycle setpoint";
CM_ SG_ 2298970120 Phase_W_9 "The actual PWM duty cycle setpoint";
CM_ SG_ 2298970121 Current_setpoint_9 "The actual current setpoint";
CM_ SG_ 2298970121 Voltage_setpoint_9 "The actual voltage setpoint";
CM_ SG_ 2298970121 Frequency_setpoint_9 "The actual frequency setpoint";
CM_ SG_ 2298937440 Keep_Alive_Enable_9 "If set to 1, module will expect to receive this message every second repeatedly, or it will stop operation";
CM_ SG_ 2298937408 Converter_ON_9 "Enable the converter.";
CM_ SG_ 2298937408 PWM_ON_9 "Enable the PWM control mode.";
CM_ SG_ 2298937408 DC_Current_feedback_ON_9 "Enable the DC current loop";
CM_ SG_ 2298937408 AC_Current_feedback_ON_9 "Enable the AC current loop";
CM_ SG_ 2298937408 Buck_ON_9 "Enable the buck control mode.";
CM_ SG_ 2298937408 Boost_ON_9 "Enable the boost control mode.";
CM_ SG_ 2298937408 Rectifier_3ph_ON_9 "Enable the three-phase rectifier control mode.";
CM_ SG_ 2298937408 Inverter_1ph_ON_9 "Enable the single-phase inverter control mode.";
CM_ SG_ 2298937408 Rectifier_1ph_ON_9 "Enable the single-phase rectifier control mode.";
CM_ SG_ 2298937408 Boost_Neutral_ON_9 "Enable the boost control mode with neutral generation.";
CM_ SG_ 2298937408 Inverter_3ph_ON_9 "Enable the three-phase inverter control mode.";
CM_ SG_ 2298937408 Inverter_1ph_Sync_ON_9 "Single-phase inverter control mode with phase synchronization.";
CM_ SG_ 2298937408 Neutral_ON_9 "Open-loop neutral generation.";
CM_ SG_ 2298937408 Rectifier_1ph_Buck_ON_9 "Single-phase rectifier with buck on one leg.";
CM_ SG_ 2298937408 Inverter_1ph_Boost_ON_9 "Single-phase inverter with boost on one leg.";
CM_ SG_ 2298937408 Rectifier_Distributed_ON_9 "Single-phase (floating) distributed rectifier";
CM_ SG_ 2298937408 MPPT_buck_ON_9 "MPPT buck";
CM_ SG_ 2298937408 MPPT_boost_ON_9 "MPPT boost";
CM_ SG_ 2298937408 Buck_2p_float_ON_9 "Boost on L1 and L2. Floating L3 (high-impedance)";
CM_ SG_ 2298937408 Inverter_1ph_Distributed_ON_9 "Single-phase inverter mode distributed";
CM_ SG_ 2298937424 Clear_Interlock_9 "Clears the converter interlock";
CM_ SG_ 2298937424 Reset_Processor_9 "Reset the converter DSP";
CM_ SG_ 2298937424 Trip_Interlock_9 "Trip the inetrnal Interlock";
CM_ SG_ 2298937409 Reactive_current_setpoint_9 "This defines reactive current setpoint for 3-phase rectifier mode";
CM_ SG_ 2298937410 Phase_U_9 "The actual PWM duty cycle setpoint";
CM_ SG_ 2298937410 Phase_V_9 "The actual PWM duty cycle setpoint";
CM_ SG_ 2298937410 Phase_W_9 "The actual PWM duty cycle setpoint";
CM_ SG_ 2298937411 Current_setpoint_9 "Sets the output current setpoint. Active only when the current loop is enabled";
CM_ SG_ 2298937412 Voltage_setpoint_9 "Sets the output voltage setpoint. Active only when the voltage loop is enabled";
CM_ SG_ 2298937416 Frequency_setpoint_9 "Sets the frequency for single-phase and three-phase generator modes.";
CM_ SG_ 2298937417 Phase_setpoint_9 "Sets the phase for inverter control modes.";
CM_ SG_ 2298937413 Stack_position_9 "The converter position within the stack";
CM_ SG_ 2298937413 Stack_size_9 "How many PFC converters are in stack in total";
CM_ SG_ 2298937413 SN_number_9 "Unique module serial number";
CM_ SG_ 2298937392 Phase_voltage_min_9 "Minimum tolerated phase voltage";
CM_ SG_ 2298937392 Phase_voltage_max_9 "Maximum allowable phase voltage";
CM_ SG_ 2298937392 DC_voltage_min_9 "Minimum allowable dc voltage";
CM_ SG_ 2298937392 DC_voltage_max_9 "Maximum allowable dc voltage";
CM_ SG_ 2298937393 Phase_current_min_9 "Minimum allowable output current";
CM_ SG_ 2298937393 Phase_current_max_9 "Maximum allowable output current";
CM_ SG_ 2298937420 Group_ID_9 "Desired group ID for the device";
CM_ SG_ 2298970127 Group_ID_9 "Group ID of the device";
CM_ SG_ 2298937441 Factory_mode_9 "Customers MUST NOT USE this bit. If set to 1, module will enter in factory mode. ";
CM_ SG_ 2298937441 Silent_CAN_mode_9 "Customers MUST NOT USE this bit. If set to 1, module will enter in factory mode. ";
CM_ SG_ 2298937418 start_9 "Start automatic calibration. Multiplexer index must be 0!";
CM_ SG_ 2298937419 point_9 "Calibration point index.";
CM_ SG_ 2298937414 CRC_9 "Checksum of bytes 0 to 3, CRC-CCITT, corresponding to qChecksum (www.qt.io)";
CM_ SG_ 2298937415 CRC_9 "Checksum of bytes 0 to 3, CRC-CCITT, corresponding to qChecksum (www.qt.io)";
CM_ SG_ 2298970198 Current_U_High_9 "This flag is set if a hight current on U tripped the internal interlock";
CM_ SG_ 2298970198 Current_U_Low_9 "This flag is set if a low current on U tripped the internal interlock";
CM_ SG_ 2298970198 Current_V_High_9 "This flag is set if a hight current on V tripped the internal interlock";
CM_ SG_ 2298970198 Current_V_Low_9 "This flag is set if a low current on V tripped the internal interlock";
CM_ SG_ 2298970198 Current_W_High_9 "This flag is set if a hight current on W tripped the internal interlock";
CM_ SG_ 2298970198 Current_W_Low_9 "This flag is set if a low current on W tripped the internal interlock";
CM_ SG_ 2298970198 Voltage_DC_9 "This flag is set if a voltage on DC tripped the internal interlock";
CM_ SG_ 2298970198 Reboot_9 "This flag is set if a reboot tripped the internal interlock";
CM_ SG_ 2298970198 Unknown_9 "This flag the reason for the internal interlock is unknown";

BA_DEF_ BO_ "SystemMessageLongSymbol" STRING;

BA_ "SystemMessageLongSymbol" BO_ 2298937409 "AFE_Reactive_Current_Setpoint_Control_9";

VAL_ 2298970112 Device_type_9 7 "AFE";
VAL_ 2298970118 Protection_trip_internal_9 1 "fault";
VAL_ 2298970118 Protection_trip_external_9 1 "fault";
VAL_ 2298970118 Phase_U_overcurrent_9 1 "fault";
VAL_ 2298970118 Phase_U_overvoltage_9 1 "fault";
VAL_ 2298970118 Phase_U_undervoltage_9 1 "fault";
VAL_ 2298970118 Phase_V_overvoltage_9 1 "fault";
VAL_ 2298970118 Phase_V_undervoltage_9 1 "fault";
VAL_ 2298970118 Phase_V_overcurrent_9 1 "fault";
VAL_ 2298970118 Phase_W_overvoltage_9 1 "fault";
VAL_ 2298970118 Phase_W_undervoltage_9 1 "fault";
VAL_ 2298970118 Phase_W_overcurrent_9 1 "fault";
VAL_ 2298970118 DC_undervoltage_9 1 "fault";
VAL_ 2298970118 DC_overvoltage_9 1 "fault";
VAL_ 2298970118 MOSFET_overtemperature_9 1 "fault";
VAL_ 2298970118 Inductor_overtemperature_9 1 "fault";
VAL_ 2298970118 Keep_Alive_not_served_9 1 "fault";
VAL_ 2298970118 PLL_not_locked_9 1 "fault";
VAL_ 2298970118 NFO_9 1 "fault";
VAL_ 2298970118 Measurement_system_failure_9 1 "fault";
VAL_ 2298970118 EEPROM_failure_9 1 "fault";
VAL_ 2298970118 System_9 1 "fault";
VAL_ 2298970198 Current_U_High_9 1 "fault";
VAL_ 2298970198 Current_U_Low_9 1 "fault";
VAL_ 2298970198 Current_V_High_9 1 "fault";
VAL_ 2298970198 Current_V_Low_9 1 "fault";
VAL_ 2298970198 Current_W_High_9 1 "fault";
VAL_ 2298970198 Current_W_Low_9 1 "fault";
VAL_ 2298970198 Voltage_DC_9 1 "fault";
VAL_ 2298970198 Reboot_9 1 "fault";
VAL_ 2298970198 Unknown_9 1 "fault";
SIG_VALTYPE_ 2298970193 Current_U_9 : 1;
SIG_VALTYPE_ 2298970193 Current_V_9 : 1;
SIG_VALTYPE_ 2298970193 Current_W_9 : 1;
SIG_VALTYPE_ 2298970193 Voltage_U_9 : 1;
SIG_VALTYPE_ 2298970193 Voltage_V_9 : 1;
SIG_VALTYPE_ 2298970193 Voltage_W_9 : 1;
SIG_VALTYPE_ 2298970193 Voltage_DC_9 : 1;
SIG_VALTYPE_ 2298970194 Current_U_9 : 1;
SIG_VALTYPE_ 2298970194 Current_V_9 : 1;
SIG_VALTYPE_ 2298970194 Current_W_9 : 1;
SIG_VALTYPE_ 2298970194 Voltage_U_9 : 1;
SIG_VALTYPE_ 2298970194 Voltage_V_9 : 1;
SIG_VALTYPE_ 2298970194 Voltage_W_9 : 1;
SIG_VALTYPE_ 2298970194 Voltage_DC_9 : 1;
